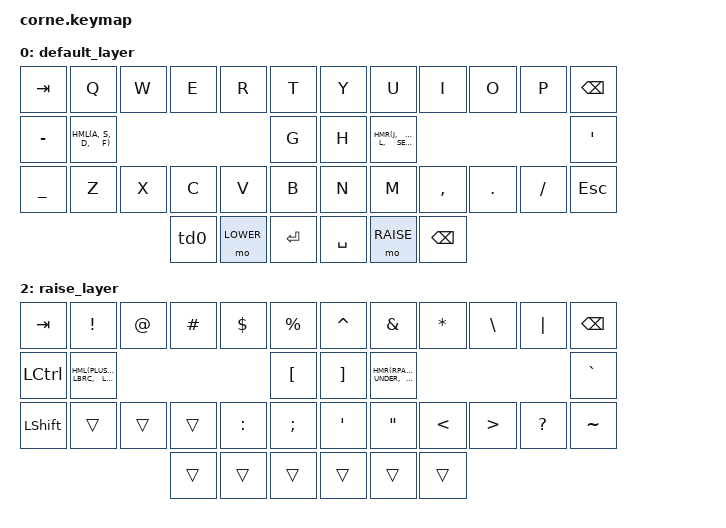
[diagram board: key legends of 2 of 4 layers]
/*
 * Copyright (c) 2020 The ZMK Contributors
 *
 * SPDX-License-Identifier: MIT
 */

#include <behaviors.dtsi>
#include <dt-bindings/zmk/keys.h>
#include <dt-bindings/zmk/bt.h>

#define LOWER 1
#define RAISE 2
#define TRI 3

#define KEYS_L 0 1 2 3 4 5 12 13 14 15 16 17 24 25 26 27 28 29
#define KEYS_R 6 7 8 9 10 11 18 19 20 21 22 23 30 31 32 33 34 35
#define THUMBS 36 37 38 39 40 41

#define HML(a, b, c, d) &hml LGUI a &hml LALT b &hml LSHIFT c &hml LCTL d
#define HMR(a, b, c, d) &hmr RCTL a &hmr RSHIFT b &hmr RALT c &hmr RGUI d


&sk {
        quick-release;
};

/ {
        behaviors {
                hml: hml { // home row mod left
                        compatible = "zmk,behavior-hold-tap";
                        #binding-cells = <2>;
                        flavor = "balanced";
                        tapping-term-ms = <280>;
                        quick-tap-ms = <175>;
                        require-prior-idle-ms = <150>;
                        bindings = <&kp>, <&kp>;
                        hold-trigger-key-positions = <KEYS_R THUMBS>;
                        hold-trigger-on-release;
                };
                hmr: hmr { // home row mod right
                        compatible = "zmk,behavior-hold-tap";
                        #binding-cells = <2>;
                        flavor = "balanced";
                        tapping-term-ms = <280>;
                        quick-tap-ms = <175>;
                        require-prior-idle-ms = <150>;
                        bindings = <&kp>, <&kp>;
                        hold-trigger-key-positions = <KEYS_L THUMBS>;
                        hold-trigger-on-release;
                };
                td0: tap_dance_0 {
                        compatible = "zmk,behavior-tap-dance";
                        #binding-cells = <0>;
                        tapping-term-ms = <200>;
                        bindings = <&sk LSHIFT>, <&caps_word>;
                };
        };

        conditional_layers {
                compatible = "zmk,conditional-layers";
                tri_layer {
                        if-layers = <LOWER RAISE>;
                        then-layer = <TRI>;
                };
        };

        keymap {
                compatible = "zmk,keymap";

                default_layer {
// -----------------------------------------------------------------------------------------
// |  TAB |  Q  |  W  |  E  |  R  |  T  |   |  Y  |  U   |  I  |  O  |  P  | BSPC |
// | CTRL |  A  |  S  |  D  |  F  |  G  |   |  H  |  J   |  K  |  L  |  ;  |  '   |
// | SHFT |  Z  |  X  |  C  |  V  |  B  |   |  N  |  M   |  ,  |  .  |  /  | ESC  |
//                    | CPW | LWR | SPC |   | ENT | RSE  | BSPC |
                        bindings = <
   &kp TAB   &kp Q  &kp W &kp E &kp R     &kp T    &kp Y     &kp U     &kp I     &kp O   &kp P    &kp BSPC
   &kp MINUS HML(A, S,    D,    F)        &kp G    &kp H     HMR(J,    K,        L,      SEMI)    &kp SQT
   &kp UNDER &kp Z  &kp X &kp C &kp V     &kp B    &kp N     &kp M     &kp COMMA &kp DOT &kp FSLH &kp ESC
                          &td0  &mo LOWER &kp RET  &kp SPACE &mo RAISE &kp BSPC
                        >;
                };
                lower_layer {
// -----------------------------------------------------------------------------------------
// | TAB |     |  7  |  8  |  9  |     |   |     |     |  *  |     |     | BSPC |
// |  -  |  0  |  4  |  5  |  6  |  0  |   | LFT | DWN |  UP | RGT |  =  |      |
// |  _  |  0  |  1  |  2  |  3  |  0  |   |     |     |     |     |  /  |      |
//                   |     |     |     |   |     |     |     |
                        bindings = <
   &kp TAB   &trans  &kp N7 &kp N8 &kp N9 &trans  &trans   &trans   &kp ASTRK &trans    &trans    &kp BSPC
   &kp MINUS HML(N0, N4,    N5,    N6)    &kp N0  &kp LEFT &kp DOWN &kp UP    &kp RIGHT &kp EQUAL &trans
   &kp UNDER &kp N0  &kp N1 &kp N2 &kp N3 &kp N0  &trans   &trans   &trans    &trans    &kp FSLH  &trans
                           &trans &trans &trans  &trans   &trans   &trans
                        >;
                };

                raise_layer {
// -----------------------------------------------------------------------------------------
// |  TAB |  !  |  @  |  #  |  $  |  %  |   |  ^  |  &  |  *  |  \  |  |  | BSPC |
// | CTRL |  +  |  -  |  {  |  (  |  [  |   |  ]  |  )  |  }  |  _  |  =  |  `   |
// | SHFT |     |     |     |  :  |  ;  |   |  '  |  "  |  <  |  >  |  ?  |  ~   |
//                    |     |     |     |   |     |     |     |
                        bindings = <
   &kp TAB   &kp EXCL  &kp AT &kp HASH &kp DLLR  &kp PRCNT  &kp CARET &kp AMPS  &kp ASTRK &kp BSLH  &kp PIPE  &kp BSPC
   &kp LCTRL HML(PLUS, MINUS, LBRC,    LPAR)     &kp LBKT   &kp RBKT  HMR(RPAR, RBRC,     UNDER,    EQUAL)    &kp GRAVE
   &kp LSHFT &trans    &trans &trans   &kp COLON &kp SEMI   &kp SQT   &kp DQT   &kp LT    &kp GT    &kp QMARK &kp TILDE
                                &trans   &trans    &trans     &trans    &trans   &trans
                        >;
                };

                tri_layer {
// -----------------------------------------------------------------------------------------
// |  TAB |  F1 |  F2 |  F3 |  F4 |  F5 |   |  F6 |  F7 |  F8 |  F9 | F10 | F11 |
// |      | BT1 | BT2 | BT3 | BT4 | BT5 |   | LFT | DWN |  UP | RGT |     | F12 |
// | BTCLR|     |     |     |     |     |   |     |     |     |     |     |     |
//                    |     |     |     |   |     |     |     |
                        bindings = <
   &kp TAB    &kp F1       &kp F2       &kp F3       &kp F4       &kp F5        &kp F6   &kp F7   &kp F8 &kp F9    &kp F10 &kp F11
   &trans     &kp LGUI     &kp LALT     &kp LSHFT    &kp LCTRL    &trans        &kp LEFT &kp DOWN &kp UP &kp RIGHT &trans  &kp F12
   &bt BT_CLR &bt BT_SEL 0 &bt BT_SEL 1 &bt BT_SEL 2 &bt BT_SEL 3 &bt BT_SEL 4  &trans   &trans   &trans &trans    &trans  &trans
                                        &trans       &trans       &trans        &trans   &trans   &trans
                        >;
                };
        };
};
